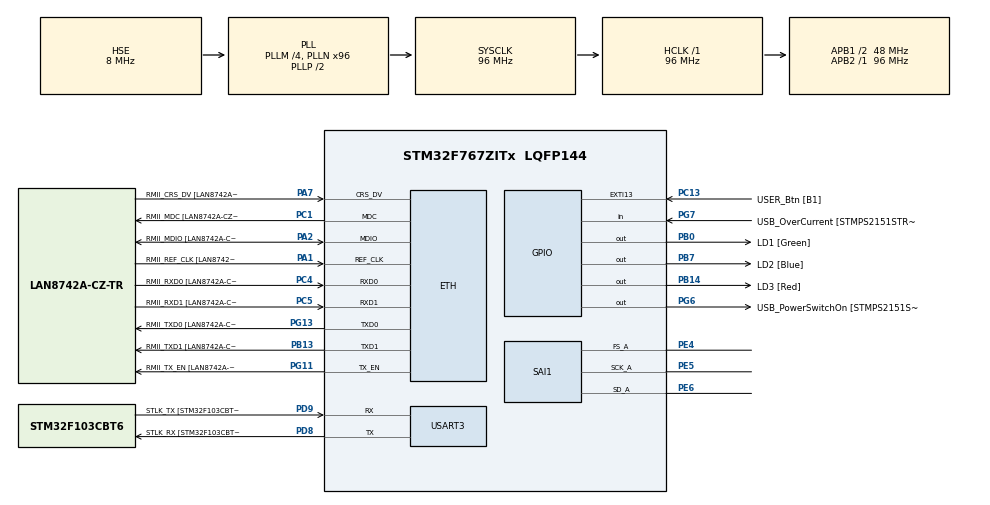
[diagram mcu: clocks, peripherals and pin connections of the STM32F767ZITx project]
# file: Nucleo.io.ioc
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ETH.MediaInterface=ETH_MEDIA_INTERFACE_RMII
FREERTOS.Tasks01=lwIP,24,128,StartlwIP,Default,NULL,Dynamic,NULL,NULL;PTPd,40,128,StartPTPd,Default,NULL,Dynamic,NULL,NULL;Logger,8,128,StartLogger,Default,NULL,Dynamic,NULL,NULL
LWIP.LWIP_TFTP=0
LWIP.Version=v2.1.2_Cube
Mcu.Family=STM32F7
Mcu.Name=STM32F767ZITx
Mcu.Package=LQFP144
NVIC.ETH_IRQn=true\:5\:0\:false\:false\:true\:true\:false\:true
NVIC.PriorityGroup=NVIC_PRIORITYGROUP_4
NVIC.TIM6_DAC_IRQn=true\:0\:0\:false\:false\:true\:false\:false\:true
NVIC.TimeBase=TIM6_DAC_IRQn
NVIC.TimeBaseIP=TIM6
PA1.GPIO_Label=RMII_REF_CLK [LAN8742A-CZ-TR_REFCLK0]
PA1.Mode=RMII
PA1.Signal=ETH_REF_CLK
PA10.GPIO_Label=USB_ID
PA10.Signal=USB_OTG_FS_ID
PA11.GPIO_Label=USB_DM
PA11.Signal=USB_OTG_FS_DM
PA12.GPIO_Label=USB_DP
PA12.Signal=USB_OTG_FS_DP
PA13.GPIO_Label=TMS
PA13.Mode=Serial_Wire
PA13.Signal=SYS_JTMS-SWDIO
PA14.GPIO_Label=TCK
PA14.Mode=Serial_Wire
PA14.Signal=SYS_JTCK-SWCLK
PA2.GPIO_Label=RMII_MDIO [LAN8742A-CZ-TR_MDIO]
PA2.Mode=RMII
PA2.Signal=ETH_MDIO
PA7.GPIO_Label=RMII_CRS_DV [LAN8742A-CZ-TR_CRS_DV]
PA7.Mode=RMII
PA7.Signal=ETH_CRS_DV
PA8.GPIO_Label=USB_SOF [TP1]
PA8.Signal=USB_OTG_FS_SOF
PA9.GPIO_Label=USB_VBUS
PA9.Signal=USB_OTG_FS_VBUS
PB0.GPIO_Label=LD1 [Green]
PB0.Signal=GPIO_Output
PB13.GPIO_Label=RMII_TXD1 [LAN8742A-CZ-TR_TXD1]
PB13.Mode=RMII
PB13.Signal=ETH_TXD1
PB14.GPIO_Label=LD3 [Red]
PB14.Signal=GPIO_Output
PB3.GPIO_Label=SWO
PB3.Signal=SYS_JTDO-SWO
PB7.GPIO_Label=LD2 [Blue]
PB7.Signal=GPIO_Output
PC1.GPIO_Label=RMII_MDC [LAN8742A-CZ-TR_MDC]
PC1.Mode=RMII
PC1.Signal=ETH_MDC
PC13.GPIO_Label=USER_Btn [B1]
PC13.Signal=GPXTI13
PC14/OSC32_IN.Mode=LSE-External-Oscillator
PC14/OSC32_IN.Signal=RCC_OSC32_IN
PC15/OSC32_OUT.Mode=LSE-External-Oscillator
PC15/OSC32_OUT.Signal=RCC_OSC32_OUT
PC4.GPIO_Label=RMII_RXD0 [LAN8742A-CZ-TR_RXD0]
PC4.Mode=RMII
PC4.Signal=ETH_RXD0
PC5.GPIO_Label=RMII_RXD1 [LAN8742A-CZ-TR_RXD1]
PC5.Mode=RMII
PC5.Signal=ETH_RXD1
PD8.GPIO_Label=STLK_RX [STM32F103CBT6_PA3]
PD8.Mode=Asynchronous
PD8.Signal=USART3_TX
PD9.GPIO_Label=STLK_TX [STM32F103CBT6_PA2]
PD9.Mode=Asynchronous
PD9.Signal=USART3_RX
PE4.Mode=SAI_A_Master
PE4.Signal=SAI1_FS_A
PE5.Mode=SAI_A_Master
PE5.Signal=SAI1_SCK_A
PE6.Mode=SAI_A_Master
PE6.Signal=SAI1_SD_A
PG11.GPIO_Label=RMII_TX_EN [LAN8742A-CZ-TR_TXEN]
PG11.Mode=RMII
PG11.Signal=ETH_TX_EN
PG13.GPIO_Label=RMII_TXD0 [LAN8742A-CZ-TR_TXD0]
PG13.Mode=RMII
PG13.Signal=ETH_TXD0
PG6.GPIO_Label=USB_PowerSwitchOn [STMPS2151STR_EN]
PG6.Signal=GPIO_Output
PG7.GPIO_Label=USB_OverCurrent [STMPS2151STR_FAULT]
PG7.Signal=GPIO_Input
PH0/OSC_IN.GPIO_Label=MCO [STM32F103CBT6_PA8]
PH0/OSC_IN.Mode=HSE-External-Clock-Source
PH0/OSC_IN.Signal=RCC_OSC_IN
PH1/OSC_OUT.Mode=HSE-External-Clock-Source
PH1/OSC_OUT.Signal=RCC_OSC_OUT
ProjectManager.HeapSize=0x200
ProjectManager.StackSize=0x400
ProjectManager.TargetToolchain=STM32CubeIDE
RCC.48MHZClocksFreq_Value=24000000
RCC.AHBFreq_Value=96000000
RCC.APB1CLKDivider=RCC_HCLK_DIV2
RCC.APB1Freq_Value=48000000
RCC.APB1TimFreq_Value=96000000
RCC.APB2Freq_Value=96000000
RCC.APB2TimFreq_Value=96000000
RCC.CortexFreq_Value=96000000
RCC.HCLKFreq_Value=96000000
RCC.HSE_VALUE=8000000
RCC.HSI_VALUE=16000000
RCC.PLLM=4
RCC.PLLMUL=RCC_PLL_MUL9
RCC.PLLN=96
RCC.PLLQ=4
RCC.PLLSAIQ=6
RCC.PLLSourceVirtual=RCC_PLLSOURCE_HSE
RCC.PRESCALERUSB=RCC_USBCLKSOURCE_PLL_DIV1_5
RCC.SYSCLKFreq_VALUE=96000000
RCC.SYSCLKSource=RCC_SYSCLKSOURCE_PLLCLK
RCC.SYSCLKSourceVirtual=RCC_SYSCLKSOURCE_PLLCLK
RCC.USBFreq_Value=48000000
RCC.VCOOutputFreq_Value=192000000
SAI1.AudioFrequency-SAI_A_Master=SAI_AUDIO_FREQUENCY_44K
SAI1.ErrorAudioFreq-SAI_A_Master=-5.3 %
SAI1.FSDefinition-SAI_A_Master=SAI_FS_STARTFRAME
SAI1.Instance-SAI_A_Master=SAI$Index_Block_A
SAI1.MClockEnable-SAI_A_Master=SAI_MASTERCLOCK_DISABLE
SAI1.RealAudioFreq-SAI_A_Master=41.666 KHz
SAI1.VirtualMode-SAI_A_Master=VM_MASTER
USART3.VirtualMode-Asynchronous=VM_ASYNC
VP_FREERTOS_VS_CMSIS_V2.Mode=CMSIS_V2
VP_LWIP_VS_Enabled.Mode=Enabled
VP_SYS_VS_tim6.Mode=TIM6
board=NUCLEO-F767ZI

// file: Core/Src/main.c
/* USER CODE BEGIN Header */
/**
  ******************************************************************************
  * @file           : main.c
  * @brief          : Main program body
  ******************************************************************************
  * @attention
  *
  * <h2><center>&copy; Copyright (c) 2020 STMicroelectronics.
  * All rights reserved.</center></h2>
  *
  * This software component is licensed by ST under BSD 3-Clause license,
  * the "License"; You may not use this file except in compliance with the
  * License. You may obtain a copy of the License at:
  *                        opensource.org/licenses/BSD-3-Clause
  *
  ******************************************************************************
  */
/* USER CODE END Header */

#include "main.h"
#include "cmsis_os.h"
#include "lwip.h"

/* USER CODE BEGIN Includes */
#include <string.h>

/* USER CODE END Includes */

SAI_HandleTypeDef hsai_BlockA1;

UART_HandleTypeDef huart3;

/* Definitions for lwIP */
osThreadId_t lwIPHandle;
const osThreadAttr_t lwIP_attributes = {
  .name = "lwIP",
  .priority = (osPriority_t) osPriorityNormal,
  .stack_size = 128 * 4
};
/* Definitions for PTPd */
osThreadId_t PTPdHandle;
const osThreadAttr_t PTPd_attributes = {
  .name = "PTPd",
  .priority = (osPriority_t) osPriorityHigh,
  .stack_size = 128 * 4
};
/* Definitions for Logger */
osThreadId_t LoggerHandle;
const osThreadAttr_t Logger_attributes = {
  .name = "Logger",
  .priority = (osPriority_t) osPriorityLow,
  .stack_size = 128 * 4
};

void SystemClock_Config(void);
static void MX_GPIO_Init(void);
static void MX_USART3_UART_Init(void);
static void MX_SAI1_Init(void);
void StartlwIP(void *argument);
void StartPTPd(void *argument);
void StartLogger(void *argument);

int main(void)
{

  /* MCU Configuration--------------------------------------------------------*/

  /* Reset of all peripherals, Initializes the Flash interface and the Systick. */
  HAL_Init();

  /* Configure the system clock */
  SystemClock_Config();

  /* Initialize all configured peripherals */
  MX_GPIO_Init();
  MX_USART3_UART_Init();
  MX_SAI1_Init();

  /* Init scheduler */
  osKernelInitialize();

  /* Create the thread(s) */
  /* creation of lwIP */
  lwIPHandle = osThreadNew(StartlwIP, NULL, &lwIP_attributes);

  /* creation of PTPd */
  PTPdHandle = osThreadNew(StartPTPd, NULL, &PTPd_attributes);

  /* creation of Logger */
  LoggerHandle = osThreadNew(StartLogger, NULL, &Logger_attributes);

  /* Start scheduler */
  osKernelStart();

  /* We should never get here as control is now taken by the scheduler */
  /* Infinite loop */
  while (1)
  {

  }
}

void SystemClock_Config(void)
{
  RCC_OscInitTypeDef RCC_OscInitStruct = {0};
  RCC_ClkInitTypeDef RCC_ClkInitStruct = {0};
  RCC_PeriphCLKInitTypeDef PeriphClkInitStruct = {0};

  /** Configure LSE Drive Capability
  */
  HAL_PWR_EnableBkUpAccess();
  /** Configure the main internal regulator output voltage
  */
  __HAL_RCC_PWR_CLK_ENABLE();
  __HAL_PWR_VOLTAGESCALING_CONFIG(PWR_REGULATOR_VOLTAGE_SCALE3);
  /** Initializes the CPU, AHB and APB busses clocks
  */
  RCC_OscInitStruct.OscillatorType = RCC_OSCILLATORTYPE_HSE;
  RCC_OscInitStruct.HSEState = RCC_HSE_BYPASS;
  RCC_OscInitStruct.PLL.PLLState = RCC_PLL_ON;
  RCC_OscInitStruct.PLL.PLLSource = RCC_PLLSOURCE_HSE;
  RCC_OscInitStruct.PLL.PLLM = 4;
  RCC_OscInitStruct.PLL.PLLN = 96;
  RCC_OscInitStruct.PLL.PLLP = RCC_PLLP_DIV2;
  RCC_OscInitStruct.PLL.PLLQ = 4;
  if (HAL_RCC_OscConfig(&RCC_OscInitStruct) != HAL_OK)
  {
    Error_Handler();
  }
  /** Activate the Over-Drive mode
  */
  if (HAL_PWREx_EnableOverDrive() != HAL_OK)
  {
    Error_Handler();
  }
  /** Initializes the CPU, AHB and APB busses clocks
  */
  RCC_ClkInitStruct.ClockType = RCC_CLOCKTYPE_HCLK|RCC_CLOCKTYPE_SYSCLK
                              |RCC_CLOCKTYPE_PCLK1|RCC_CLOCKTYPE_PCLK2;
  RCC_ClkInitStruct.SYSCLKSource = RCC_SYSCLKSOURCE_PLLCLK;
  RCC_ClkInitStruct.AHBCLKDivider = RCC_SYSCLK_DIV1;
  RCC_ClkInitStruct.APB1CLKDivider = RCC_HCLK_DIV2;
  RCC_ClkInitStruct.APB2CLKDivider = RCC_HCLK_DIV1;

  if (HAL_RCC_ClockConfig(&RCC_ClkInitStruct, FLASH_LATENCY_3) != HAL_OK)
  {
    Error_Handler();
  }
  PeriphClkInitStruct.PeriphClockSelection = RCC_PERIPHCLK_USART3|RCC_PERIPHCLK_SAI1;
  PeriphClkInitStruct.PLLSAI.PLLSAIN = 192;
  PeriphClkInitStruct.PLLSAI.PLLSAIR = 2;
  PeriphClkInitStruct.PLLSAI.PLLSAIQ = 6;
  PeriphClkInitStruct.PLLSAI.PLLSAIP = RCC_PLLSAIP_DIV2;
  PeriphClkInitStruct.PLLSAIDivQ = 1;
  PeriphClkInitStruct.PLLSAIDivR = RCC_PLLSAIDIVR_2;
  PeriphClkInitStruct.Sai1ClockSelection = RCC_SAI1CLKSOURCE_PLLSAI;
  PeriphClkInitStruct.Usart3ClockSelection = RCC_USART3CLKSOURCE_PCLK1;
  if (HAL_RCCEx_PeriphCLKConfig(&PeriphClkInitStruct) != HAL_OK)
  {
    Error_Handler();
  }
}

static void MX_SAI1_Init(void)
{

  hsai_BlockA1.Instance = SAI1_Block_A;
  hsai_BlockA1.Init.Protocol = SAI_FREE_PROTOCOL;
  hsai_BlockA1.Init.AudioMode = SAI_MODEMASTER_TX;
  hsai_BlockA1.Init.DataSize = SAI_DATASIZE_8;
  hsai_BlockA1.Init.FirstBit = SAI_FIRSTBIT_MSB;
  hsai_BlockA1.Init.ClockStrobing = SAI_CLOCKSTROBING_FALLINGEDGE;
  hsai_BlockA1.Init.Synchro = SAI_ASYNCHRONOUS;
  hsai_BlockA1.Init.OutputDrive = SAI_OUTPUTDRIVE_DISABLE;
  hsai_BlockA1.Init.NoDivider = SAI_MASTERDIVIDER_ENABLE;
  hsai_BlockA1.Init.FIFOThreshold = SAI_FIFOTHRESHOLD_EMPTY;
  hsai_BlockA1.Init.AudioFrequency = SAI_AUDIO_FREQUENCY_44K;
  hsai_BlockA1.Init.SynchroExt = SAI_SYNCEXT_DISABLE;
  hsai_BlockA1.Init.MonoStereoMode = SAI_STEREOMODE;
  hsai_BlockA1.Init.CompandingMode = SAI_NOCOMPANDING;
  hsai_BlockA1.Init.TriState = SAI_OUTPUT_NOTRELEASED;
  hsai_BlockA1.FrameInit.FrameLength = 8;
  hsai_BlockA1.FrameInit.ActiveFrameLength = 1;
  hsai_BlockA1.FrameInit.FSDefinition = SAI_FS_STARTFRAME;
  hsai_BlockA1.FrameInit.FSPolarity = SAI_FS_ACTIVE_LOW;
  hsai_BlockA1.FrameInit.FSOffset = SAI_FS_FIRSTBIT;
  hsai_BlockA1.SlotInit.FirstBitOffset = 0;
  hsai_BlockA1.SlotInit.SlotSize = SAI_SLOTSIZE_DATASIZE;
  hsai_BlockA1.SlotInit.SlotNumber = 1;
  hsai_BlockA1.SlotInit.SlotActive = 0x00000000;
  if (HAL_SAI_Init(&hsai_BlockA1) != HAL_OK)
  {
    Error_Handler();
  }

}

static void MX_USART3_UART_Init(void)
{

  huart3.Instance = USART3;
  huart3.Init.BaudRate = 115200;
  huart3.Init.WordLength = UART_WORDLENGTH_8B;
  huart3.Init.StopBits = UART_STOPBITS_1;
  huart3.Init.Parity = UART_PARITY_NONE;
  huart3.Init.Mode = UART_MODE_TX_RX;
  huart3.Init.HwFlowCtl = UART_HWCONTROL_NONE;
  huart3.Init.OverSampling = UART_OVERSAMPLING_16;
  huart3.Init.OneBitSampling = UART_ONE_BIT_SAMPLE_DISABLE;
  huart3.AdvancedInit.AdvFeatureInit = UART_ADVFEATURE_NO_INIT;
  if (HAL_UART_Init(&huart3) != HAL_OK)
  {
    Error_Handler();
  }

}

static void MX_GPIO_Init(void)
{
  GPIO_InitTypeDef GPIO_InitStruct = {0};

  /* GPIO Ports Clock Enable */
  __HAL_RCC_GPIOE_CLK_ENABLE();
  __HAL_RCC_GPIOC_CLK_ENABLE();
  __HAL_RCC_GPIOH_CLK_ENABLE();
  __HAL_RCC_GPIOA_CLK_ENABLE();
  __HAL_RCC_GPIOB_CLK_ENABLE();
  __HAL_RCC_GPIOD_CLK_ENABLE();
  __HAL_RCC_GPIOG_CLK_ENABLE();

  /*Configure GPIO pin Output Level */
  HAL_GPIO_WritePin(GPIOB, LD1_Pin|LD3_Pin|LD2_Pin, GPIO_PIN_RESET);

  /*Configure GPIO pin Output Level */
  HAL_GPIO_WritePin(USB_PowerSwitchOn_GPIO_Port, USB_PowerSwitchOn_Pin, GPIO_PIN_RESET);

  /*Configure GPIO pin : USER_Btn_Pin */
  GPIO_InitStruct.Pin = USER_Btn_Pin;
  GPIO_InitStruct.Mode = GPIO_MODE_IT_RISING;
  GPIO_InitStruct.Pull = GPIO_NOPULL;
  HAL_GPIO_Init(USER_Btn_GPIO_Port, &GPIO_InitStruct);

  /*Configure GPIO pins : LD1_Pin LD3_Pin LD2_Pin */
  GPIO_InitStruct.Pin = LD1_Pin|LD3_Pin|LD2_Pin;
  GPIO_InitStruct.Mode = GPIO_MODE_OUTPUT_PP;
  GPIO_InitStruct.Pull = GPIO_NOPULL;
  GPIO_InitStruct.Speed = GPIO_SPEED_FREQ_LOW;
  HAL_GPIO_Init(GPIOB, &GPIO_InitStruct);

  /*Configure GPIO pin : USB_PowerSwitchOn_Pin */
  GPIO_InitStruct.Pin = USB_PowerSwitchOn_Pin;
  GPIO_InitStruct.Mode = GPIO_MODE_OUTPUT_PP;
  GPIO_InitStruct.Pull = GPIO_NOPULL;
  GPIO_InitStruct.Speed = GPIO_SPEED_FREQ_LOW;
  HAL_GPIO_Init(USB_PowerSwitchOn_GPIO_Port, &GPIO_InitStruct);

  /*Configure GPIO pin : USB_OverCurrent_Pin */
  GPIO_InitStruct.Pin = USB_OverCurrent_Pin;
  GPIO_InitStruct.Mode = GPIO_MODE_INPUT;
  GPIO_InitStruct.Pull = GPIO_NOPULL;
  HAL_GPIO_Init(USB_OverCurrent_GPIO_Port, &GPIO_InitStruct);

  /*Configure GPIO pins : USB_SOF_Pin USB_ID_Pin USB_DM_Pin USB_DP_Pin */
  GPIO_InitStruct.Pin = USB_SOF_Pin|USB_ID_Pin|USB_DM_Pin|USB_DP_Pin;
  GPIO_InitStruct.Mode = GPIO_MODE_AF_PP;
  GPIO_InitStruct.Pull = GPIO_NOPULL;
  GPIO_InitStruct.Speed = GPIO_SPEED_FREQ_VERY_HIGH;
  GPIO_InitStruct.Alternate = GPIO_AF10_OTG_FS;
  HAL_GPIO_Init(GPIOA, &GPIO_InitStruct);

  /*Configure GPIO pin : USB_VBUS_Pin */
  GPIO_InitStruct.Pin = USB_VBUS_Pin;
  GPIO_InitStruct.Mode = GPIO_MODE_INPUT;
  GPIO_InitStruct.Pull = GPIO_NOPULL;
  HAL_GPIO_Init(USB_VBUS_GPIO_Port, &GPIO_InitStruct);

}

void StartlwIP(void *argument)
{
  /* init code for LWIP */
  MX_LWIP_Init();
  /* USER CODE BEGIN 5 */

  /* Infinite loop */
  for(;;)
  {
	osDelay(1);
  }

  osThreadTerminate(NULL);
  /* USER CODE END 5 */
}

void StartPTPd(void *argument)
{
  /* USER CODE BEGIN StartPTPd */
  /* Infinite loop */
  for(;;)
  {
	HAL_GPIO_TogglePin(GPIOB, GPIO_PIN_0);
    osDelay(500);
  }

  osThreadTerminate(NULL);
  /* USER CODE END StartPTPd */
}

void StartLogger(void *argument)
{
  /* USER CODE BEGIN StartLogger */
  /* Infinite loop */
  for(;;)
  {
    char* mesg = "Nucleo.io\n";

	HAL_UART_Transmit(&huart3, (uint8_t *)mesg, strlen(mesg), 0xFFFF);
	osDelay(1000);
  }

  osThreadTerminate(NULL);
  /* USER CODE END StartLogger */
}

 /**
  * @brief  Period elapsed callback in non blocking mode
  * @note   This function is called  when TIM6 interrupt took place, inside
  * HAL_TIM_IRQHandler(). It makes a direct call to HAL_IncTick() to increment
  * a global variable "uwTick" used as application time base.
  * @param  htim : TIM handle
  * @retval None
  */
void HAL_TIM_PeriodElapsedCallback(TIM_HandleTypeDef *htim)
{
  if (htim->Instance == TIM6) {
    HAL_IncTick();
  }
}

void Error_Handler(void)
{
}

/************************ (C) COPYRIGHT STMicroelectronics *****END OF FILE****/
